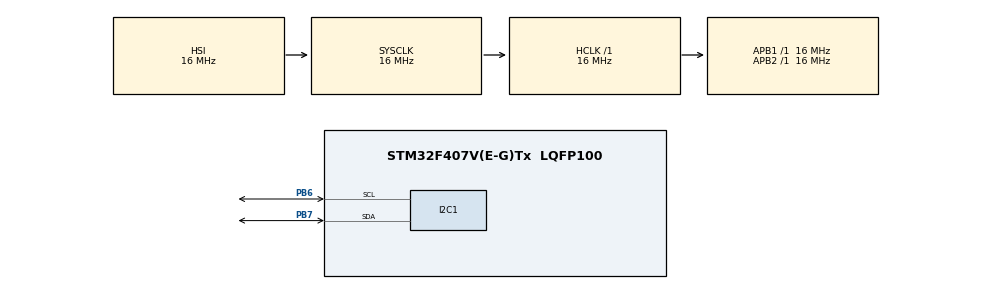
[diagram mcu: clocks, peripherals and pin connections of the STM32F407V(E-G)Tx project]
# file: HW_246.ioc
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Mcu.Family=STM32F4
Mcu.Name=STM32F407V(E-G)Tx
Mcu.Package=LQFP100
NVIC.PriorityGroup=NVIC_PRIORITYGROUP_4
PB6.Mode=I2C
PB6.Signal=I2C1_SCL
PB7.Mode=I2C
PB7.Signal=I2C1_SDA
ProjectManager.HeapSize=0x200
ProjectManager.StackSize=0x400
ProjectManager.TargetToolchain=STM32CubeIDE
RCC.AHBFreq_Value=16000000
RCC.APB1Freq_Value=16000000
RCC.APB2Freq_Value=16000000
RCC.CortexFreq_Value=16000000
RCC.HSE_VALUE=25000000
RCC.HSI_VALUE=16000000
RCC.LSE_VALUE=32768
RCC.SYSCLKFreq_VALUE=16000000
RCC.VCOOutputFreq_Value=192000000
board=custom

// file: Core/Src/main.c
/* USER CODE BEGIN Header */
/**
 ******************************************************************************
 * @file           : main.c
 * @brief          : Main program body
 ******************************************************************************
 * @attention
 *
 * Copyright (c) 2026 STMicroelectronics.
 * All rights reserved.
 *
 * This software is licensed under terms that can be found in the LICENSE file
 * in the root directory of this software component.
 * If no LICENSE file comes with this software, it is provided AS-IS.
 *
 ******************************************************************************
 */
/* USER CODE END Header */
#include "main.h"

/* USER CODE BEGIN PD */

#define QMC5883P_WRITE_ADDR 	0x58
#define QMC5883P_READ_ADDR		0x59

/* USER CODE END PD */

I2C_HandleTypeDef hi2c1;

/* USER CODE BEGIN PV */

typedef struct {

	int16_t x_mag;
	int16_t y_mag;
	int16_t z_mag;

} QMC5883P_MAGNETOMETER;

QMC5883P_MAGNETOMETER mag_g;

uint16_t error_count;

/* USER CODE END PV */

void SystemClock_Config(void);
static void MX_GPIO_Init(void);
static void MX_I2C1_Init(void);

/* USER CODE BEGIN 0 */

uint8_t QMC5883P_Get_Values(QMC5883P_MAGNETOMETER *out) {

	uint8_t buffer[6] = { 0 };

	if (HAL_I2C_Mem_Read(&hi2c1, QMC5883P_READ_ADDR, 0x01, I2C_MEMADD_SIZE_8BIT,
			buffer, 6, 100) != HAL_OK) {
		uint32_t err = HAL_I2C_GetError(&hi2c1);

		error_count++;

		return 0;
	}

	//HAL_I2C_Mem_Read(&hi2c1, QMC5883P_READ_ADDR, 0x01, I2C_MEMADD_SIZE_8BIT,buffer, 6, 100);
	out->x_mag = (int16_t) ((buffer[1] << 8) | buffer[0]);
	out->y_mag = (int16_t) ((buffer[3] << 8) | buffer[2]);
	out->z_mag = (int16_t) ((buffer[5] << 8) | buffer[4]);

	return 1;
}

uint8_t QMC5883P_Init(uint8_t period_cfg, uint8_t set_reset, uint8_t ctrl_reg1) {

	//Device check
	uint8_t chip_id;

	HAL_I2C_Mem_Read(&hi2c1, QMC5883P_WRITE_ADDR, 0x00, I2C_MEMADD_SIZE_8BIT,
			&chip_id, 1, 100);

	if (chip_id != 0x80) {
		return 0;
	}

	HAL_I2C_Mem_Write(&hi2c1, QMC5883P_WRITE_ADDR, 0x29,
	I2C_MEMADD_SIZE_8BIT, &period_cfg, 1, 100);

	HAL_I2C_Mem_Write(&hi2c1, QMC5883P_WRITE_ADDR, 0x0B,
	I2C_MEMADD_SIZE_8BIT, &set_reset, 1, 100);

	HAL_I2C_Mem_Write(&hi2c1, QMC5883P_WRITE_ADDR, 0x0A,
	I2C_MEMADD_SIZE_8BIT, &ctrl_reg1, 1, 100);

	return 1;
}

uint8_t QMC5883P_Init_Default(void) {

// Period: 0x06, Set/Reset: 0x08, Ctrl1 (200Hz, +-30G, Cont.): 0xCF
	return QMC5883P_Init(0x06, 0x08, 0xCF);
}
/* USER CODE END 0 */

int main(void) {

	/* MCU Configuration--------------------------------------------------------*/

	/* Reset of all peripherals, Initializes the Flash interface and the Systick. */
	HAL_Init();

	/* Configure the system clock */
	SystemClock_Config();

	/* Initialize all configured peripherals */
	MX_GPIO_Init();
	MX_I2C1_Init();
	/* USER CODE BEGIN 2 */

	QMC5883P_Init_Default();

	/* USER CODE END 2 */

	/* Infinite loop */
	while (1) {

		/* USER CODE BEGIN 3 */

		QMC5883P_Get_Values(&mag_g);

		HAL_Delay(1000);

	}
	/* USER CODE END 3 */
}

void SystemClock_Config(void) {
	RCC_OscInitTypeDef RCC_OscInitStruct = { 0 };
	RCC_ClkInitTypeDef RCC_ClkInitStruct = { 0 };

	/** Configure the main internal regulator output voltage
	 */
	__HAL_RCC_PWR_CLK_ENABLE();
	__HAL_PWR_VOLTAGESCALING_CONFIG(PWR_REGULATOR_VOLTAGE_SCALE1);

	/** Initializes the RCC Oscillators according to the specified parameters
	 * in the RCC_OscInitTypeDef structure.
	 */
	RCC_OscInitStruct.OscillatorType = RCC_OSCILLATORTYPE_HSI;
	RCC_OscInitStruct.HSIState = RCC_HSI_ON;
	RCC_OscInitStruct.HSICalibrationValue = RCC_HSICALIBRATION_DEFAULT;
	RCC_OscInitStruct.PLL.PLLState = RCC_PLL_NONE;
	if (HAL_RCC_OscConfig(&RCC_OscInitStruct) != HAL_OK) {
		Error_Handler();
	}

	/** Initializes the CPU, AHB and APB buses clocks
	 */
	RCC_ClkInitStruct.ClockType = RCC_CLOCKTYPE_HCLK | RCC_CLOCKTYPE_SYSCLK
			| RCC_CLOCKTYPE_PCLK1 | RCC_CLOCKTYPE_PCLK2;
	RCC_ClkInitStruct.SYSCLKSource = RCC_SYSCLKSOURCE_HSI;
	RCC_ClkInitStruct.AHBCLKDivider = RCC_SYSCLK_DIV1;
	RCC_ClkInitStruct.APB1CLKDivider = RCC_HCLK_DIV1;
	RCC_ClkInitStruct.APB2CLKDivider = RCC_HCLK_DIV1;

	if (HAL_RCC_ClockConfig(&RCC_ClkInitStruct, FLASH_LATENCY_0) != HAL_OK) {
		Error_Handler();
	}
}

static void MX_I2C1_Init(void) {

	hi2c1.Instance = I2C1;
	hi2c1.Init.ClockSpeed = 100000;
	hi2c1.Init.DutyCycle = I2C_DUTYCYCLE_2;
	hi2c1.Init.OwnAddress1 = 0;
	hi2c1.Init.AddressingMode = I2C_ADDRESSINGMODE_7BIT;
	hi2c1.Init.DualAddressMode = I2C_DUALADDRESS_DISABLE;
	hi2c1.Init.OwnAddress2 = 0;
	hi2c1.Init.GeneralCallMode = I2C_GENERALCALL_DISABLE;
	hi2c1.Init.NoStretchMode = I2C_NOSTRETCH_DISABLE;
	if (HAL_I2C_Init(&hi2c1) != HAL_OK) {
		Error_Handler();
	}

}

static void MX_GPIO_Init(void) {

	/* GPIO Ports Clock Enable */
	__HAL_RCC_GPIOB_CLK_ENABLE();

}

void Error_Handler(void) {
	__disable_irq();
	while (1) {
	}
}
